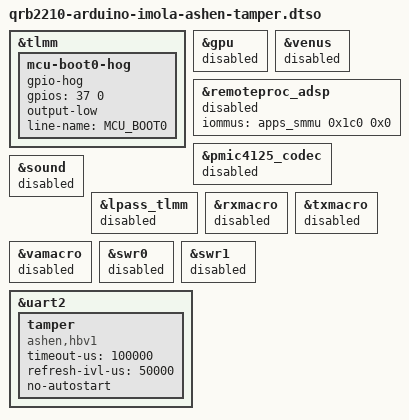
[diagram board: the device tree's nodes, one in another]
// SPDX-License-Identifier: BSD-3-Clause
/*
 * Ashen tamper/heartbeat MCU link on the UNO Q's QRB2210<->STM32U585 UART.
 */

/dts-v1/;
/plugin/;

&tlmm {
	/*
	 * GPIO_37 drives the MCU's BOOT0 through a TXS0104 level shifter, whose
	 * pull-ups win when the pin is undriven. Hold it low so every MCU reset
	 * (tamper self-reset, SWD flashing) boots ashen-fw from flash instead of
	 * the STM32 ROM bootloader.
	 */
	mcu-boot0-hog {
		gpio-hog;
		gpios = <37 0>;
		output-low;
		line-name = "MCU_BOOT0";
	};
};

/*
 * The demo only needs the display (KMS) for the console; the Adreno GPU fails
 * to initialise (-EINVAL) and its retries put errors on the console.
 */
&gpu {
	status = "disabled";
};

/*
 * No audio or video codec in the demo. The ADSP firmware fails to load, so the
 * LPASS audio blocks only defer forever and print warnings onto the console;
 * venus fails on its firmware too (QHEE did its PIL memory assignment as well).
 */
&venus { status = "disabled"; };

/*
 * Linux runs at EL2 here (QHEE is torn down for KVM), so nothing does QHEE's PIL
 * work anymore (SHM bridges, mapping the carveout for the subsystem's SMMU
 * stream): the ADSP's PAS INIT_IMAGE then fails with -EINVAL. With the ADSP's
 * firmware stream ID given, qcom_q6v5_pas does that work itself, as in the
 * upstream *-el2.dtso overlays. 0x1c0 is the base of agatti's LPASS SID block
 * (q6asm uses 0x1c1, the fastrpc compute banks 0x1c3 and up).
 * Authentication then passes, but the ADSP never signals ready (no SMMU faults,
 * hyp-assigning the carveout to VMIDs 6/0x16 does not help either), so it stays
 * off: the demo has no audio, and the boot saves the 5 s start timeout.
 */
&remoteproc_adsp {
	iommus = <&apps_smmu 0x1c0 0x0>;
	status = "disabled";
};
&pmic4125_codec { status = "disabled"; };
&sound { status = "disabled"; };
&lpass_tlmm { status = "disabled"; };
&rxmacro { status = "disabled"; };
&txmacro { status = "disabled"; };
&vamacro { status = "disabled"; };
&swr0 { status = "disabled"; };
&swr1 { status = "disabled"; };

&uart2 {
	status = "okay";

	tamper: tamper {
		compatible = "ashen,hbv1";
		timeout-us = <100000>;
		refresh-ivl-us = <50000>;
		/* armed from userspace once paired, see demo/ashen-pair */
		no-autostart;
	};
};
